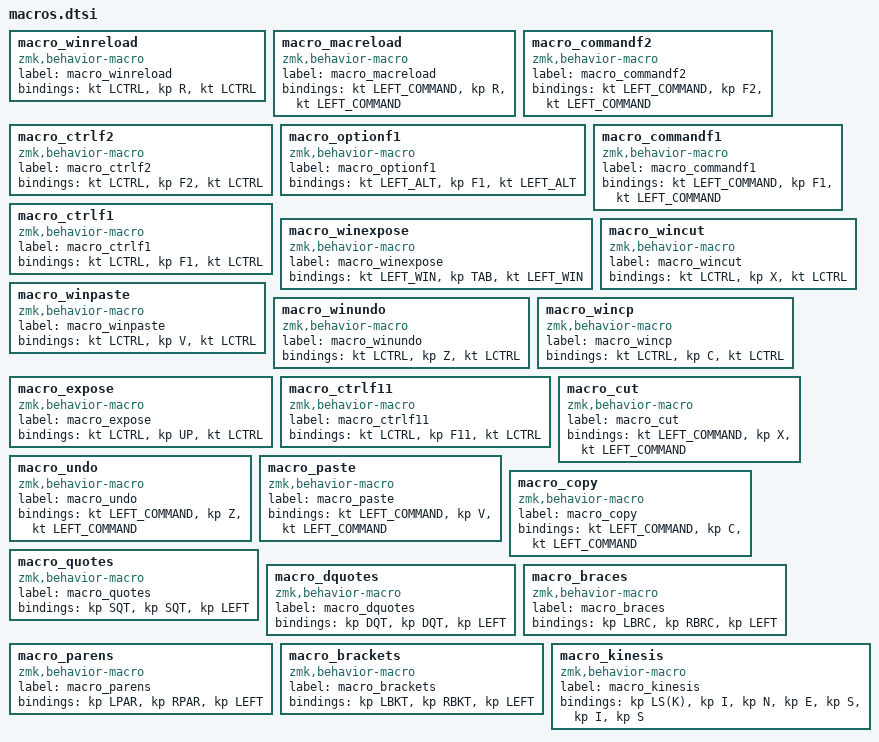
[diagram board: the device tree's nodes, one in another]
macro_winreload: macro_winreload{
compatible = "zmk,behavior-macro";
label = "macro_winreload";
#binding-cells = <0>;
bindings = <&kt LCTRL>, <&kp R>, <&kt LCTRL>;
};
macro_macreload: macro_macreload{
compatible = "zmk,behavior-macro";
label = "macro_macreload";
#binding-cells = <0>;
bindings = <&kt LEFT_COMMAND>, <&kp R>, <&kt LEFT_COMMAND>;
};
macro_commandf2: macro_commandf2{
compatible = "zmk,behavior-macro";
label = "macro_commandf2";
#binding-cells = <0>;
bindings = <&kt LEFT_COMMAND>, <&kp F2>, <&kt LEFT_COMMAND>;
};
macro_ctrlf2: macro_ctrlf2{
compatible = "zmk,behavior-macro";
label = "macro_ctrlf2";
#binding-cells = <0>;
bindings = <&kt LCTRL>, <&kp F2>, <&kt LCTRL>;
};
macro_optionf1: macro_optionf1{
compatible = "zmk,behavior-macro";
label = "macro_optionf1";
#binding-cells = <0>;
bindings = <&kt LEFT_ALT>, <&kp F1>, <&kt LEFT_ALT>;
};
macro_commandf1: macro_commandf1{
compatible = "zmk,behavior-macro";
label = "macro_commandf1";
#binding-cells = <0>;
bindings = <&kt LEFT_COMMAND>, <&kp F1>, <&kt LEFT_COMMAND>;
};
macro_ctrlf1: macro_ctrlf1{
compatible = "zmk,behavior-macro";
label = "macro_ctrlf1";
#binding-cells = <0>;
bindings = <&kt LCTRL>, <&kp F1>, <&kt LCTRL>;
};
macro_winexpose: macro_winexpose{
compatible = "zmk,behavior-macro";
label = "macro_winexpose";
#binding-cells = <0>;
bindings = <&kt LEFT_WIN>, <&kp TAB>, <&kt LEFT_WIN>;
};
macro_wincut: macro_wincut{
compatible = "zmk,behavior-macro";
label = "macro_wincut";
#binding-cells = <0>;
bindings = <&kt LCTRL>, <&kp X>, <&kt LCTRL>;
};
macro_winpaste: macro_winpaste{
compatible = "zmk,behavior-macro";
label = "macro_winpaste";
#binding-cells = <0>;
bindings = <&kt LCTRL>, <&kp V>, <&kt LCTRL>;
};
macro_winundo: macro_winundo{
compatible = "zmk,behavior-macro";
label = "macro_winundo";
#binding-cells = <0>;
bindings = <&kt LCTRL>, <&kp Z>, <&kt LCTRL>;
};
macro_wincp: macro_wincp{
compatible = "zmk,behavior-macro";
label = "macro_wincp";
#binding-cells = <0>;
bindings = <&kt LCTRL>, <&kp C>, <&kt LCTRL>;
};
macro_expose: macro_expose{
compatible = "zmk,behavior-macro";
label = "macro_expose";
#binding-cells = <0>;
bindings = <&kt LCTRL>, <&kp UP>, <&kt LCTRL>;
};
macro_ctrlf11: macro_ctrlf11{
compatible = "zmk,behavior-macro";
label = "macro_ctrlf11";
#binding-cells = <0>;
bindings = <&kt LCTRL>, <&kp F11>, <&kt LCTRL>;
};
macro_cut: macro_cut{
compatible = "zmk,behavior-macro";
label = "macro_cut";
#binding-cells = <0>;
bindings = <&kt LEFT_COMMAND>, <&kp X>, <&kt LEFT_COMMAND>;
};
macro_undo: macro_undo{
compatible = "zmk,behavior-macro";
label = "macro_undo";
#binding-cells = <0>;
bindings = <&kt LEFT_COMMAND>, <&kp Z>, <&kt LEFT_COMMAND>;
};
macro_paste: macro_paste{
compatible = "zmk,behavior-macro";
label = "macro_paste";
#binding-cells = <0>;
bindings = <&kt LEFT_COMMAND>, <&kp V>, <&kt LEFT_COMMAND>;
};
macro_copy: macro_copy{
compatible = "zmk,behavior-macro";
label = "macro_copy";
#binding-cells = <0>;
bindings = <&kt LEFT_COMMAND>, <&kp C>, <&kt LEFT_COMMAND>;
};
macro_quotes: macro_quotes{
compatible = "zmk,behavior-macro";
label = "macro_quotes";
#binding-cells = <0>;
bindings = <&kp SQT>, <&kp SQT>, <&kp LEFT>;
};
macro_dquotes: macro_dquotes{
compatible = "zmk,behavior-macro";
label = "macro_dquotes";
#binding-cells = <0>;
bindings = <&kp DQT>, <&kp DQT>, <&kp LEFT>;
};
macro_braces: macro_braces{
compatible = "zmk,behavior-macro";
label = "macro_braces";
#binding-cells = <0>;
bindings = <&kp LBRC>, <&kp RBRC>, <&kp LEFT>;
};
macro_parens: macro_parens{
compatible = "zmk,behavior-macro";
label = "macro_parens";
#binding-cells = <0>;
bindings = <&kp LPAR>, <&kp RPAR>, <&kp LEFT>;
};
macro_brackets: macro_brackets{
compatible = "zmk,behavior-macro";
label = "macro_brackets";
#binding-cells = <0>;
bindings = <&kp LBKT>, <&kp RBKT>, <&kp LEFT>;
};
macro_kinesis: macro_kinesis{
compatible = "zmk,behavior-macro";
label = "macro_kinesis";
#binding-cells = <0>;
bindings = <&kp LS(K)>, <&kp I>, <&kp N>, <&kp E>, <&kp S>, <&kp I>, <&kp S>;
};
